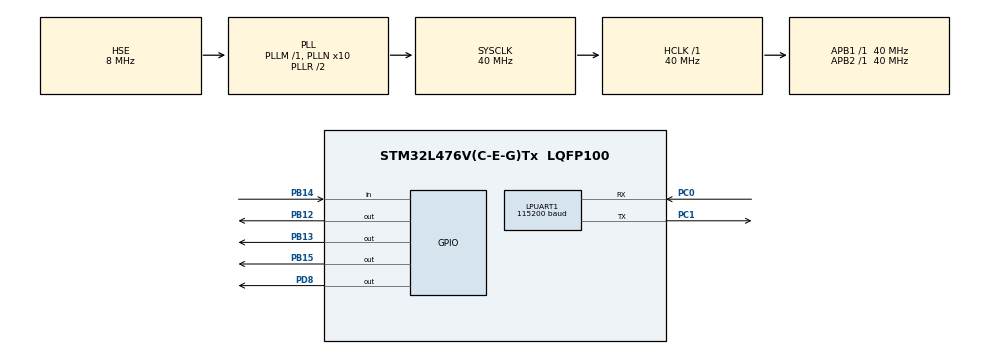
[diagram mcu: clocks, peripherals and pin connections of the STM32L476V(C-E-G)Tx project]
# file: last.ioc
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LPUART1.BaudRate=115200
LPUART1.WordLength=UART_WORDLENGTH_8B
Mcu.Family=STM32L4
Mcu.Name=STM32L476V(C-E-G)Tx
Mcu.Package=LQFP100
NVIC.PriorityGroup=NVIC_PRIORITYGROUP_4
PA13\ (JTMS-SWDIO).Signal=SYS_JTMS-SWDIO
PA14\ (JTCK-SWCLK).Signal=SYS_JTCK-SWCLK
PB12.Signal=GPIO_Output
PB13.Signal=GPIO_Output
PB14.Signal=GPIO_Input
PB15.Signal=GPIO_Output
PC0.Mode=Asynchronous
PC0.Signal=LPUART1_RX
PC1.Mode=Asynchronous
PC1.Signal=LPUART1_TX
PC14-OSC32_IN\ (PC14).Mode=LSE-External-Oscillator
PC14-OSC32_IN\ (PC14).Signal=RCC_OSC32_IN
PC15-OSC32_OUT\ (PC15).Mode=LSE-External-Oscillator
PC15-OSC32_OUT\ (PC15).Signal=RCC_OSC32_OUT
PD8.Signal=GPIO_Output
PH0-OSC_IN\ (PH0).Mode=HSE-External-Oscillator
PH0-OSC_IN\ (PH0).Signal=RCC_OSC_IN
PH1-OSC_OUT\ (PH1).Mode=HSE-External-Oscillator
PH1-OSC_OUT\ (PH1).Signal=RCC_OSC_OUT
ProjectManager.HeapSize=0x200
ProjectManager.StackSize=0x800
ProjectManager.TargetToolchain=MDK-ARM V5
RCC.ADCFreq_Value=32000000
RCC.AHBFreq_Value=40000000
RCC.APB1Freq_Value=40000000
RCC.APB1TimFreq_Value=40000000
RCC.APB2Freq_Value=40000000
RCC.APB2TimFreq_Value=40000000
RCC.CortexFreq_Value=40000000
RCC.HCLKFreq_Value=40000000
RCC.HSE_VALUE=8000000
RCC.HSI_VALUE=16000000
RCC.MSI_VALUE=4000000
RCC.PLLN=10
RCC.PLLSourceVirtual=RCC_PLLSOURCE_HSE
RCC.SYSCLKFreq_VALUE=40000000
RCC.SYSCLKSource=RCC_SYSCLKSOURCE_PLLCLK
RCC.USBFreq_Value=32000000
RCC.VCOOutputFreq_Value=80000000
board=custom

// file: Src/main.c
/* USER CODE BEGIN Header */
/**
  ******************************************************************************
  * @file           : main.c
  * @brief          : Main program body
  ******************************************************************************
  * @attention
  *
  * <h2><center>&copy; Copyright (c) 2019 STMicroelectronics.
  * All rights reserved.</center></h2>
  *
  * This software component is licensed by ST under BSD 3-Clause license,
  * the "License"; You may not use this file except in compliance with the
  * License. You may obtain a copy of the License at:
  *                        opensource.org/licenses/BSD-3-Clause
  *
  ******************************************************************************
  */
/* USER CODE END Header */

#include "main.h"
#include "parameter.h"
#include "Task.h"
#include "Thread.h"
#include "airthmetic.h"

UART_HandleTypeDef hlpuart1;

void SystemClock_Config(void);
static void MX_GPIO_Init(void);
static void MX_LPUART1_UART_Init(void);

/* USER CODE BEGIN 0 */
uint8_t flashreadbuf[4096];
uint8_t flashwritebuf[4096];
uint8_t ReadFlash28data[28];

uint8_t Flag_Super=0;
uint8_t testas2[28] ={0x12,0x34,0x56,0x78,
                     0x87,0x65,0x43,0x21,
                     0x11,0x22,0x33,0x44,
                     0x55,0x66,0x77,0x88,
                     0x00,0x02,             //cp
                     0x00,0x02,0x2c,0xfc,   //length
                     0x08,0x00,0x60,0x00,   //sp
                     0xa3,0xb1};            //crc

//uint8_t testas1[28] ={0x12,0x34,0x56,0x78,
//                     0x87,0x65,0x43,0x21,
//                     0x11,0x22,0x33,0x44,
//                     0x55,0x66,0x77,0x88,
//                     0x00,0x01,             //cp
//                     0x00,0x02,0x2c,0xfc,   //length
//                     0x08,0x00,0x60,0x00,   //sp
//                     0x53,0xa5};            //crc

uint8_t testas1[28] ={0x78,0x56,0x34,0x12,
                     0x21,0x43,0x65,0x87,
                     0x44,0x33,0x22,0x11,
                     0x88,0x77,0x66,0x55,
                     0x00,0x00,             //cp
                     0x64,0x33,0x02,0x00,   //length
                     0x00,0x60,0x00,0x08,   //sp
                     0xc3,0xef};            //crc

uint8_t testas3[28] ={0x12,0x34,0x56,0x78,
                     0x87,0x65,0x43,0x21,
                     0x11,0x22,0x33,0x44,
                     0x55,0x66,0x77,0x88,
                     0x00,0x02,             //cp
                     0x00,0x00,0x12,0x6c,   //length
                     0x08,0x00,0x60,0x00,   //sp
                     0xa0,0x56};            //crc
#include "string.h"
const uint32_t gul_UpdataMarkA_IAP[4] =
{
    0x12345678, 0x87654321, 0x11223344, 0x55667788
};

const uint32_t gul_UpdataMarkB_IAP[4] =
{
    0,0,0,0
};

uint8_t JudgeFlashFlag(void)
{
    uint8_t result=0;
    uint16_t crc123=0;
    if(memcmp(ReadFlash28data, (uint8_t *)&gul_UpdataMarkA_IAP[0],16) == 0)
    {
        crc123 = Crc_Change(ReadFlash28data,26,0,0xffff);
        if((ReadFlash28data[27]==((uint8_t)(crc123>>8)))&&(ReadFlash28data[26]==((uint8_t)crc123)))
          result = 1;
        else result = 0;
    }
    return result;
}

uint8_t Judge_Iap_Start_Flag(void)
{
    uint8_t flag = 0;
    ReadFlashData(0,28,ReadFlash28data);
    flag = JudgeFlashFlag();
    return flag;
}

uint8_t JudgeIAPKeyPress(void)
{
    uint32_t temp;
    uint16_t time=0;
    for(temp = 0;temp<2000000;temp++)
    {
        if(HAL_GPIO_ReadPin(GPIOA,GPIO_PIN_2) == 1)
            return 0;
    }
    SerialPutString("\r\n======================================================================");
    SerialPutString("\r\n=    drop the iap button in ten second~~~                            =");
    SerialPutString("\r\n======================================================================");
    for(temp = 0;temp<10000000;temp++)
    {
        if(HAL_GPIO_ReadPin(GPIOA,GPIO_PIN_2) == 1) time++;
        else time = 0;
        if(time>= 100)  return 1;
    }
    return 0;
}
/* USER CODE END 0 */

int main(void)
{

  /* MCU Configuration--------------------------------------------------------*/

  /* Reset of all peripherals, Initializes the Flash interface and the Systick. */
  HAL_Init();

  /* Configure the system clock */
  SystemClock_Config();

  /* Initialize all configured peripherals */
  MX_GPIO_Init();
  MX_LPUART1_UART_Init();
  InitialExFlashIO();
  /* USER CODE BEGIN 2 */
//  DelaySuiyi(2000000);
//  DelaySuiyi(2000000);
//    if(Flag_Super)
//        WriteFlashData(0,28,testas1);
//    ReadFlashData(0,28,ReadFlash28data);
//    ReadFlashData(0x1000,1024,flashreadbuf);

//#pragma asm
//    MOV R0,#19H
//#pragma endasm

//__ASM("MOV ABC,0");
//__ASM("ADD ABC, #1");
//JumpToApplication();
//    From_Uart_Task();
    if(JudgeIAPKeyPress()==1)   From_Uart_Task();
    else
    {
        if(Judge_Iap_Start_Flag() == 1)          IAPTask();
        else   JumpToApplication();
    }
  /* USER CODE END 2 */

  /* Infinite loop */
  while (1)
  {

  }
}

void SystemClock_Config(void)
{
  RCC_OscInitTypeDef RCC_OscInitStruct = {0};
  RCC_ClkInitTypeDef RCC_ClkInitStruct = {0};
  RCC_PeriphCLKInitTypeDef PeriphClkInit = {0};

  /** Initializes the CPU, AHB and APB busses clocks
  */
  RCC_OscInitStruct.OscillatorType = RCC_OSCILLATORTYPE_HSE;
  RCC_OscInitStruct.HSEState = RCC_HSE_ON;
  RCC_OscInitStruct.PLL.PLLState = RCC_PLL_ON;
  RCC_OscInitStruct.PLL.PLLSource = RCC_PLLSOURCE_HSE;
  RCC_OscInitStruct.PLL.PLLM = 1;
  RCC_OscInitStruct.PLL.PLLN = 10;
  RCC_OscInitStruct.PLL.PLLP = RCC_PLLP_DIV7;
  RCC_OscInitStruct.PLL.PLLQ = RCC_PLLQ_DIV2;
  RCC_OscInitStruct.PLL.PLLR = RCC_PLLR_DIV2;
  if (HAL_RCC_OscConfig(&RCC_OscInitStruct) != HAL_OK)
  {
    Error_Handler();
  }
  /** Initializes the CPU, AHB and APB busses clocks
  */
  RCC_ClkInitStruct.ClockType = RCC_CLOCKTYPE_HCLK|RCC_CLOCKTYPE_SYSCLK
                              |RCC_CLOCKTYPE_PCLK1|RCC_CLOCKTYPE_PCLK2;
  RCC_ClkInitStruct.SYSCLKSource = RCC_SYSCLKSOURCE_PLLCLK;
  RCC_ClkInitStruct.AHBCLKDivider = RCC_SYSCLK_DIV1;
  RCC_ClkInitStruct.APB1CLKDivider = RCC_HCLK_DIV1;
  RCC_ClkInitStruct.APB2CLKDivider = RCC_HCLK_DIV1;

  if (HAL_RCC_ClockConfig(&RCC_ClkInitStruct, FLASH_LATENCY_2) != HAL_OK)
  {
    Error_Handler();
  }
  PeriphClkInit.PeriphClockSelection = RCC_PERIPHCLK_LPUART1;
  PeriphClkInit.Lpuart1ClockSelection = RCC_LPUART1CLKSOURCE_PCLK1;
  if (HAL_RCCEx_PeriphCLKConfig(&PeriphClkInit) != HAL_OK)
  {
    Error_Handler();
  }
  /** Configure the main internal regulator output voltage
  */
  if (HAL_PWREx_ControlVoltageScaling(PWR_REGULATOR_VOLTAGE_SCALE1) != HAL_OK)
  {
    Error_Handler();
  }
}

static void MX_LPUART1_UART_Init(void)
{

  hlpuart1.Instance = LPUART1;
  hlpuart1.Init.BaudRate = 115200;
  hlpuart1.Init.WordLength = UART_WORDLENGTH_8B;
  hlpuart1.Init.StopBits = UART_STOPBITS_1;
  hlpuart1.Init.Parity = UART_PARITY_NONE;
  hlpuart1.Init.Mode = UART_MODE_TX_RX;
  hlpuart1.Init.HwFlowCtl = UART_HWCONTROL_NONE;
  hlpuart1.Init.OneBitSampling = UART_ONE_BIT_SAMPLE_DISABLE;
  hlpuart1.AdvancedInit.AdvFeatureInit = UART_ADVFEATURE_NO_INIT;
  if (HAL_UART_Init(&hlpuart1) != HAL_OK)
  {
    Error_Handler();
  }

}

static void MX_GPIO_Init(void)
{
  GPIO_InitTypeDef GPIO_InitStruct = {0};

  /* GPIO Ports Clock Enable */
  __HAL_RCC_GPIOE_CLK_ENABLE();
  __HAL_RCC_GPIOC_CLK_ENABLE();
  __HAL_RCC_GPIOH_CLK_ENABLE();
  __HAL_RCC_GPIOA_CLK_ENABLE();
  __HAL_RCC_GPIOB_CLK_ENABLE();
  __HAL_RCC_GPIOD_CLK_ENABLE();

  /*Configure GPIO pin Output Level */
  HAL_GPIO_WritePin(GPIOB, GPIO_PIN_12|GPIO_PIN_13|GPIO_PIN_15, GPIO_PIN_RESET);

  /*Configure GPIO pin Output Level */
  HAL_GPIO_WritePin(GPIOD, GPIO_PIN_8, GPIO_PIN_RESET);

  /*Configure GPIO pins : PE2 PE3 PE4 PE5
                           PE6 PE7 PE8 PE9
                           PE10 PE11 PE12 PE13
                           PE14 PE15 PE0 PE1 */
  GPIO_InitStruct.Pin = GPIO_PIN_2|GPIO_PIN_3|GPIO_PIN_4|GPIO_PIN_5
                          |GPIO_PIN_6|GPIO_PIN_7|GPIO_PIN_8|GPIO_PIN_9
                          |GPIO_PIN_10|GPIO_PIN_11|GPIO_PIN_12|GPIO_PIN_13
                          |GPIO_PIN_14|GPIO_PIN_15|GPIO_PIN_0|GPIO_PIN_1;
  GPIO_InitStruct.Mode = GPIO_MODE_ANALOG;
  GPIO_InitStruct.Pull = GPIO_NOPULL;
  HAL_GPIO_Init(GPIOE, &GPIO_InitStruct);

  //  /*Configure GPIO pin : PA2 */
//  GPIO_InitStruct.Pin = GPIO_PIN_7;
//  GPIO_InitStruct.Mode = GPIO_MODE_INPUT;
//  GPIO_InitStruct.Pull = GPIO_NOPULL;
//  HAL_GPIO_Init(GPIOE, &GPIO_InitStruct);

  /*Configure GPIO pins : PC13 PC2 PC3 PC4
                           PC5 PC6 PC7 PC8
                           PC9 PC10 PC11 PC12 */
  GPIO_InitStruct.Pin = GPIO_PIN_13|GPIO_PIN_2|GPIO_PIN_3|GPIO_PIN_4
                          |GPIO_PIN_5|GPIO_PIN_6|GPIO_PIN_7|GPIO_PIN_8
                          |GPIO_PIN_9|GPIO_PIN_10|GPIO_PIN_11|GPIO_PIN_12;
  GPIO_InitStruct.Mode = GPIO_MODE_ANALOG;
  GPIO_InitStruct.Pull = GPIO_NOPULL;
  HAL_GPIO_Init(GPIOC, &GPIO_InitStruct);

  /*Configure GPIO pins : PA0 PA1 PA3 PA4
                           PA5 PA6 PA7 PA8
                           PA9 PA10 PA11 PA12
                           PA15 */
  GPIO_InitStruct.Pin = GPIO_PIN_0|GPIO_PIN_1|GPIO_PIN_3|GPIO_PIN_4|GPIO_PIN_2
                          |GPIO_PIN_5|GPIO_PIN_6|GPIO_PIN_7|GPIO_PIN_8
                          |GPIO_PIN_9|GPIO_PIN_10|GPIO_PIN_11|GPIO_PIN_12
                          |GPIO_PIN_15;
  GPIO_InitStruct.Mode = GPIO_MODE_ANALOG;
  GPIO_InitStruct.Pull = GPIO_NOPULL;
  HAL_GPIO_Init(GPIOA, &GPIO_InitStruct);

//  GPIO_InitStruct.Pin = GPIO_PIN_2;
//  GPIO_InitStruct.Mode = GPIO_MODE_OUTPUT_PP;
//  GPIO_InitStruct.Pull = GPIO_PULLUP;
//  HAL_GPIO_Init(GPIOA, &GPIO_InitStruct);

//   XLB_TEST(0);
//    XLB_TEST(1);
//     XLB_TEST(0);
//      XLB_TEST(1);

  /*Configure GPIO pin : PA2 */
  GPIO_InitStruct.Pin = GPIO_PIN_2;
  GPIO_InitStruct.Mode = GPIO_MODE_INPUT;
  GPIO_InitStruct.Pull = GPIO_NOPULL;
  HAL_GPIO_Init(GPIOA, &GPIO_InitStruct);

  /*Configure GPIO pins : PB0 PB1 PB2 PB10
                           PB11 PB3 PB4 PB5
                           PB6 PB7 PB8 PB9 */
  GPIO_InitStruct.Pin = GPIO_PIN_0|GPIO_PIN_1|GPIO_PIN_2|GPIO_PIN_10
                          |GPIO_PIN_11|GPIO_PIN_3|GPIO_PIN_4|GPIO_PIN_5
                          |GPIO_PIN_6|GPIO_PIN_7|GPIO_PIN_8|GPIO_PIN_9;
  GPIO_InitStruct.Mode = GPIO_MODE_ANALOG;
  GPIO_InitStruct.Pull = GPIO_NOPULL;
  HAL_GPIO_Init(GPIOB, &GPIO_InitStruct);

  /*Configure GPIO pins : PB12 PB13 PB15 */
  GPIO_InitStruct.Pin = GPIO_PIN_12|GPIO_PIN_13|GPIO_PIN_15;
  GPIO_InitStruct.Mode = GPIO_MODE_OUTPUT_PP;
  GPIO_InitStruct.Pull = GPIO_NOPULL;
  GPIO_InitStruct.Speed = GPIO_SPEED_FREQ_LOW;
  HAL_GPIO_Init(GPIOB, &GPIO_InitStruct);

  /*Configure GPIO pin : PB14 */
  GPIO_InitStruct.Pin = GPIO_PIN_14;
  GPIO_InitStruct.Mode = GPIO_MODE_INPUT;
  GPIO_InitStruct.Pull = GPIO_NOPULL;
  HAL_GPIO_Init(GPIOB, &GPIO_InitStruct);

  /*Configure GPIO pin : PD8 */
  GPIO_InitStruct.Pin = GPIO_PIN_8;
  GPIO_InitStruct.Mode = GPIO_MODE_OUTPUT_PP;
  GPIO_InitStruct.Pull = GPIO_NOPULL;
  GPIO_InitStruct.Speed = GPIO_SPEED_FREQ_LOW;
  HAL_GPIO_Init(GPIOD, &GPIO_InitStruct);

  /*Configure GPIO pins : PD9 PD10 PD11 PD12
                           PD13 PD14 PD15 PD0
                           PD1 PD2 PD3 PD4
                           PD5 PD6 PD7 */
  GPIO_InitStruct.Pin = GPIO_PIN_9|GPIO_PIN_10|GPIO_PIN_11|GPIO_PIN_12
                          |GPIO_PIN_13|GPIO_PIN_14|GPIO_PIN_15|GPIO_PIN_0
                          |GPIO_PIN_1|GPIO_PIN_2|GPIO_PIN_3|GPIO_PIN_4
                          |GPIO_PIN_5|GPIO_PIN_6|GPIO_PIN_7;
  GPIO_InitStruct.Mode = GPIO_MODE_ANALOG;
  GPIO_InitStruct.Pull = GPIO_NOPULL;
  HAL_GPIO_Init(GPIOD, &GPIO_InitStruct);

}

void Error_Handler(void)
{
}

/************************ (C) COPYRIGHT STMicroelectronics *****END OF FILE****/
